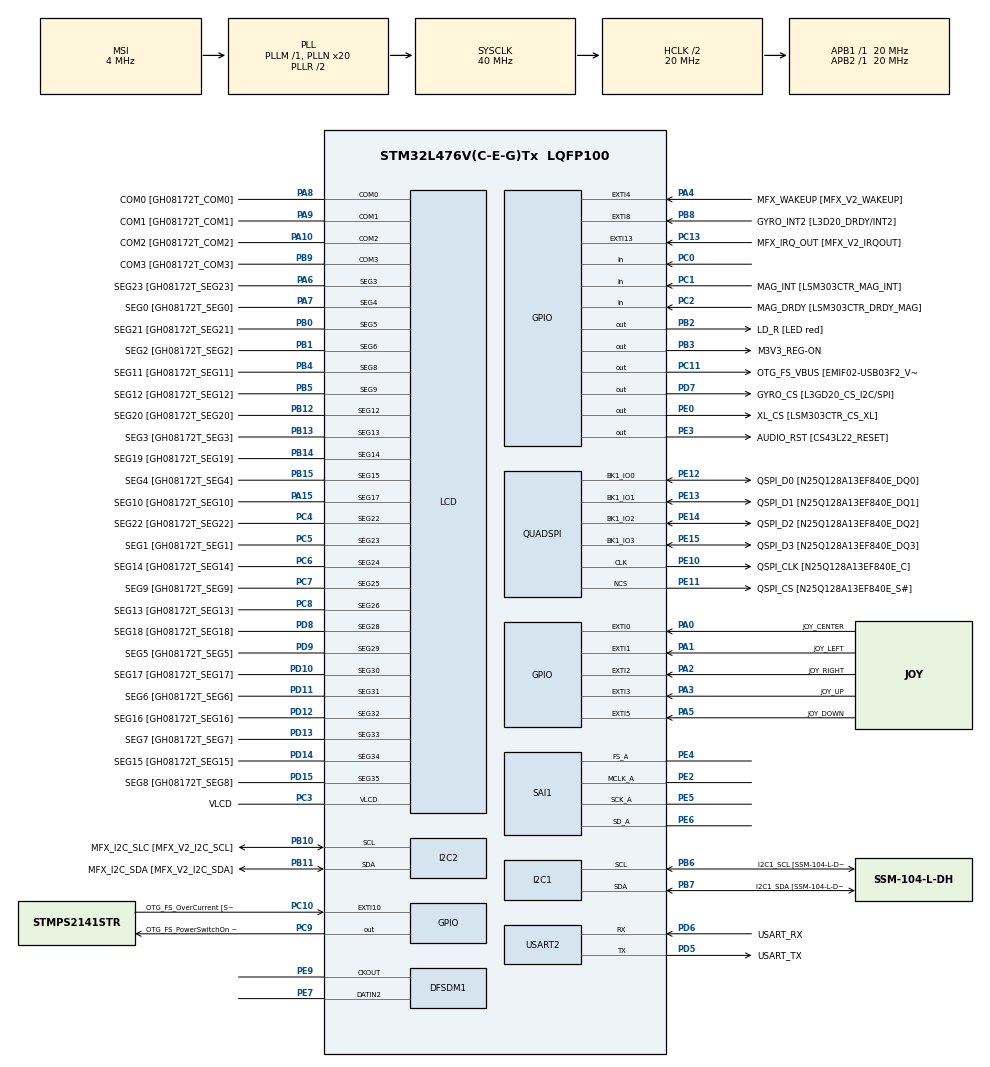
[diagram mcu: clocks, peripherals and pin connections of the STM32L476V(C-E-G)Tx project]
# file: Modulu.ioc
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DFSDM1.Divider=4
DFSDM1.DmaMode_reg_FIL0=ENABLE
DFSDM1.FastMode_reg_FIL0=ENABLE
DFSDM1.Filter_injChannel2_FIL0=DFSDM_CHANNEL_2
DFSDM1.Filter_regChannel_FIL0=DFSDM_CHANNEL_2
DFSDM1.Fosr_FIL0=64
DFSDM1.Oversampling_CH2=10
DFSDM1.RightBitShift_CH2=2
DFSDM1.ScanMode_inj_FIL0=ENABLE
DFSDM1.Selection=DFSDM_CHANNEL_OUTPUT_CLOCK_AUDIO
DFSDM1.SincOrder_FIL0=DFSDM_FILTER_SINC3_ORDER
Dma.DFSDM1_FLT0.1.Direction=DMA_PERIPH_TO_MEMORY
Dma.DFSDM1_FLT0.1.Instance=DMA1_Channel4
Dma.DFSDM1_FLT0.1.MemDataAlignment=DMA_MDATAALIGN_WORD
Dma.DFSDM1_FLT0.1.MemInc=DMA_MINC_ENABLE
Dma.DFSDM1_FLT0.1.Mode=DMA_CIRCULAR
Dma.DFSDM1_FLT0.1.PeriphDataAlignment=DMA_PDATAALIGN_WORD
Dma.DFSDM1_FLT0.1.PeriphInc=DMA_PINC_DISABLE
Dma.DFSDM1_FLT0.1.Priority=DMA_PRIORITY_VERY_HIGH
Dma.Request0=SAI1_A
Dma.Request1=DFSDM1_FLT0
Dma.SAI1_A.0.Direction=DMA_MEMORY_TO_PERIPH
Dma.SAI1_A.0.Instance=DMA2_Channel1
Dma.SAI1_A.0.MemDataAlignment=DMA_MDATAALIGN_HALFWORD
Dma.SAI1_A.0.MemInc=DMA_MINC_ENABLE
Dma.SAI1_A.0.Mode=DMA_CIRCULAR
Dma.SAI1_A.0.PeriphDataAlignment=DMA_PDATAALIGN_HALFWORD
Dma.SAI1_A.0.PeriphInc=DMA_PINC_DISABLE
Dma.SAI1_A.0.Priority=DMA_PRIORITY_HIGH
I2C1.Timing=0x00404C74
I2C2.Timing=0x00404C74
Mcu.Family=STM32L4
Mcu.Name=STM32L476V(C-E-G)Tx
Mcu.Package=LQFP100
NVIC.DFSDM1_FLT0_IRQn=true\:0\:0\:false\:false\:true\:true\:true\:true
NVIC.DMA1_Channel4_IRQn=true\:0\:0\:false\:false\:true\:false\:true\:true
NVIC.DMA2_Channel1_IRQn=true\:0\:0\:false\:false\:true\:false\:true\:true
NVIC.EXTI0_IRQn=true\:0\:0\:false\:false\:true\:true\:true\:true
NVIC.EXTI1_IRQn=true\:0\:0\:false\:false\:true\:true\:true\:true
NVIC.EXTI2_IRQn=true\:0\:0\:false\:false\:true\:true\:true\:true
NVIC.EXTI3_IRQn=true\:0\:0\:false\:false\:true\:true\:true\:true
NVIC.EXTI9_5_IRQn=true\:0\:0\:false\:false\:true\:true\:true\:true
NVIC.PVD_PVM_IRQn=true\:0\:0\:false\:false\:true\:true\:true\:true
NVIC.PriorityGroup=NVIC_PRIORITYGROUP_4
NVIC.SAI1_IRQn=true\:0\:0\:false\:false\:true\:true\:true\:true
NVIC.TIM6_DAC_IRQn=true\:0\:0\:false\:false\:true\:true\:true\:true
NVIC.TIM7_IRQn=true\:0\:0\:false\:false\:true\:true\:true\:true
PA0.GPIO_Label=JOY_CENTER
PA0.GPIO_ModeDefaultEXTI=GPIO_MODE_IT_RISING
PA0.Signal=GPXTI0
PA1.GPIO_Label=JOY_LEFT
PA1.GPIO_PuPd=GPIO_PULLDOWN
PA1.Signal=GPXTI1
PA10.GPIO_Label=COM2 [GH08172T_COM2]
PA10.GPIO_Mode=GPIO_MODE_AF_PP
PA10.GPIO_PuPd=GPIO_NOPULL
PA10.GPIO_Speed=GPIO_SPEED_FREQ_LOW
PA10.Mode=1/4 Duty Cycle
PA10.Signal=LCD_COM2
PA11.GPIO_Label=OTG_FS_DM [EMIF02-USB03F2_D-out]
PA11.GPIO_Mode=GPIO_MODE_AF_PP
PA11.GPIO_PuPd=GPIO_NOPULL
PA11.GPIO_Speed=GPIO_SPEED_FREQ_VERY_HIGH
PA11.Signal=USB_OTG_FS_DM
PA12.GPIO_Label=OTG_FS_DP [EMIF02-USB03F2_D+out]
PA12.GPIO_Mode=GPIO_MODE_AF_PP
PA12.GPIO_PuPd=GPIO_NOPULL
PA12.GPIO_Speed=GPIO_SPEED_FREQ_VERY_HIGH
PA12.Signal=USB_OTG_FS_DP
PA13\ (JTMS-SWDIO).GPIO_Label=SWDIO
PA13\ (JTMS-SWDIO).Mode=Serial_Wire
PA13\ (JTMS-SWDIO).Signal=SYS_JTMS-SWDIO
PA14\ (JTCK-SWCLK).GPIO_Label=SWCLK
PA14\ (JTCK-SWCLK).Mode=Serial_Wire
PA14\ (JTCK-SWCLK).Signal=SYS_JTCK-SWCLK
PA15\ (JTDI).GPIO_Label=SEG10 [GH08172T_SEG10]
PA15\ (JTDI).GPIO_Mode=GPIO_MODE_AF_PP
PA15\ (JTDI).GPIO_PuPd=GPIO_NOPULL
PA15\ (JTDI).GPIO_Speed=GPIO_SPEED_FREQ_LOW
PA15\ (JTDI).Mode=SEG17
PA15\ (JTDI).Signal=LCD_SEG17
PA2.GPIO_Label=JOY_RIGHT
PA2.GPIO_PuPd=GPIO_PULLDOWN
PA2.Signal=GPXTI2
PA3.GPIO_Label=JOY_UP
PA3.GPIO_PuPd=GPIO_PULLDOWN
PA3.Signal=GPXTI3
PA4.GPIO_Label=MFX_WAKEUP [MFX_V2_WAKEUP]
PA4.GPIO_ModeDefaultEXTI=GPIO_MODE_EVT_RISING
PA4.GPIO_PuPd=GPIO_NOPULL
PA4.Signal=GPXTI4
PA5.GPIO_Label=JOY_DOWN
PA5.GPIO_PuPd=GPIO_PULLDOWN
PA5.Signal=GPXTI5
PA6.GPIO_Label=SEG23 [GH08172T_SEG23]
PA6.GPIO_Mode=GPIO_MODE_AF_PP
PA6.GPIO_PuPd=GPIO_NOPULL
PA6.GPIO_Speed=GPIO_SPEED_FREQ_LOW
PA6.Mode=SEG3
PA6.Signal=LCD_SEG3
PA7.GPIO_Label=SEG0 [GH08172T_SEG0]
PA7.GPIO_Mode=GPIO_MODE_AF_PP
PA7.GPIO_PuPd=GPIO_NOPULL
PA7.GPIO_Speed=GPIO_SPEED_FREQ_LOW
PA7.Mode=SEG4
PA7.Signal=LCD_SEG4
PA8.GPIO_Label=COM0 [GH08172T_COM0]
PA8.GPIO_Mode=GPIO_MODE_AF_PP
PA8.GPIO_PuPd=GPIO_NOPULL
PA8.GPIO_Speed=GPIO_SPEED_FREQ_LOW
PA8.Mode=1/4 Duty Cycle
PA8.Signal=LCD_COM0
PA9.GPIO_Label=COM1 [GH08172T_COM1]
PA9.GPIO_Mode=GPIO_MODE_AF_PP
PA9.GPIO_PuPd=GPIO_NOPULL
PA9.GPIO_Speed=GPIO_SPEED_FREQ_LOW
PA9.Mode=1/4 Duty Cycle
PA9.Signal=LCD_COM1
PB0.GPIO_Label=SEG21 [GH08172T_SEG21]
PB0.GPIO_Mode=GPIO_MODE_AF_PP
PB0.GPIO_PuPd=GPIO_NOPULL
PB0.GPIO_Speed=GPIO_SPEED_FREQ_LOW
PB0.Mode=SEG5
PB0.Signal=LCD_SEG5
PB1.GPIO_Label=SEG2 [GH08172T_SEG2]
PB1.GPIO_Mode=GPIO_MODE_AF_PP
PB1.GPIO_PuPd=GPIO_NOPULL
PB1.GPIO_Speed=GPIO_SPEED_FREQ_LOW
PB1.Mode=SEG6
PB1.Signal=LCD_SEG6
PB10.GPIO_Label=MFX_I2C_SLC [MFX_V2_I2C_SCL]
PB10.GPIO_Mode=GPIO_MODE_AF_OD
PB10.GPIO_Pu=GPIO_PULLUP
PB10.GPIO_Speed=GPIO_SPEED_FREQ_VERY_HIGH
PB10.Mode=I2C
PB10.Signal=I2C2_SCL
PB11.GPIO_Label=MFX_I2C_SDA [MFX_V2_I2C_SDA]
PB11.GPIO_Mode=GPIO_MODE_AF_OD
PB11.GPIO_Pu=GPIO_PULLUP
PB11.GPIO_Speed=GPIO_SPEED_FREQ_VERY_HIGH
PB11.Mode=I2C
PB11.Signal=I2C2_SDA
PB12.GPIO_Label=SEG20 [GH08172T_SEG20]
PB12.GPIO_Mode=GPIO_MODE_AF_PP
PB12.GPIO_PuPd=GPIO_NOPULL
PB12.GPIO_Speed=GPIO_SPEED_FREQ_LOW
PB12.Mode=SEG12
PB12.Signal=LCD_SEG12
PB13.GPIO_Label=SEG3 [GH08172T_SEG3]
PB13.GPIO_Mode=GPIO_MODE_AF_PP
PB13.GPIO_PuPd=GPIO_NOPULL
PB13.GPIO_Speed=GPIO_SPEED_FREQ_LOW
PB13.Mode=SEG13
PB13.Signal=LCD_SEG13
PB14.GPIO_Label=SEG19 [GH08172T_SEG19]
PB14.GPIO_Mode=GPIO_MODE_AF_PP
PB14.GPIO_PuPd=GPIO_NOPULL
PB14.GPIO_Speed=GPIO_SPEED_FREQ_LOW
PB14.Mode=SEG14
PB14.Signal=LCD_SEG14
PB15.GPIO_Label=SEG4 [GH08172T_SEG4]
PB15.GPIO_Mode=GPIO_MODE_AF_PP
PB15.GPIO_PuPd=GPIO_NOPULL
PB15.GPIO_Speed=GPIO_SPEED_FREQ_LOW
PB15.Mode=SEG15
PB15.Signal=LCD_SEG15
PB2.GPIO_Label=LD_R [LED red]
PB2.GPIO_ModeDefaultOutputPP=GPIO_MODE_OUTPUT_PP
PB2.GPIO_PuPd=GPIO_PULLUP
PB2.GPIO_Speed=GPIO_SPEED_FREQ_VERY_HIGH
PB2.Signal=GPIO_Output
PB3\ (JTDO-TRACESWO).GPIO_Label=M3V3_REG-ON
PB3\ (JTDO-TRACESWO).GPIO_ModeDefaultOutputPP=GPIO_MODE_OUTPUT_PP
PB3\ (JTDO-TRACESWO).GPIO_PuPd=GPIO_NOPULL
PB3\ (JTDO-TRACESWO).GPIO_Speed=GPIO_SPEED_FREQ_LOW
PB3\ (JTDO-TRACESWO).Signal=GPIO_Output
PB4\ (NJTRST).GPIO_Label=SEG11 [GH08172T_SEG11]
PB4\ (NJTRST).GPIO_Mode=GPIO_MODE_AF_PP
PB4\ (NJTRST).GPIO_PuPd=GPIO_NOPULL
PB4\ (NJTRST).GPIO_Speed=GPIO_SPEED_FREQ_LOW
PB4\ (NJTRST).Mode=SEG8
PB4\ (NJTRST).Signal=LCD_SEG8
PB5.GPIO_Label=SEG12 [GH08172T_SEG12]
PB5.GPIO_Mode=GPIO_MODE_AF_PP
PB5.GPIO_PuPd=GPIO_NOPULL
PB5.GPIO_Speed=GPIO_SPEED_FREQ_LOW
PB5.Mode=SEG9
PB5.Signal=LCD_SEG9
PB6.GPIO_FM6=__NULL
PB6.GPIO_Label=I2C1_SCL [SSM-104-L-DH_SCL]
PB6.GPIO_Mode=GPIO_MODE_AF_OD
PB6.GPIO_Pu=GPIO_PULLUP
PB6.GPIO_Speed=GPIO_SPEED_FREQ_VERY_HIGH
PB6.Mode=I2C
PB6.Signal=I2C1_SCL
PB7.GPIO_FM7=__NULL
PB7.GPIO_Label=I2C1_SDA [SSM-104-L-DH_SDA]
PB7.GPIO_Mode=GPIO_MODE_AF_OD
PB7.GPIO_Pu=GPIO_PULLUP
PB7.GPIO_Speed=GPIO_SPEED_FREQ_VERY_HIGH
PB7.Mode=I2C
PB7.Signal=I2C1_SDA
PB8.GPIO_Label=GYRO_INT2 [L3D20_DRDY/INT2]
PB8.GPIO_ModeDefaultEXTI=GPIO_MODE_EVT_RISING
PB8.GPIO_PuPd=GPIO_NOPULL
PB8.Signal=GPXTI8
PB9.GPIO_FM9=__NULL
PB9.GPIO_Label=COM3 [GH08172T_COM3]
PB9.GPIO_Mode=GPIO_MODE_AF_PP
PB9.GPIO_PuPd=GPIO_NOPULL
PB9.GPIO_Speed=GPIO_SPEED_FREQ_LOW
PB9.Mode=1/4 Duty Cycle
PB9.Signal=LCD_COM3
PC0.Signal=GPIO_Input
PC1.GPIO_Label=MAG_INT [LSM303CTR_MAG_INT]
PC1.GPIO_Mode=GPIO_MODE_INPUT
PC1.GPIO_PuPd=GPIO_NOPULL
PC1.Signal=GPIO_Input
PC10.GPIO_Label=OTG_FS_OverCurrent [STMPS2141STR_FAULT]
PC10.GPIO_ModeDefaultEXTI=GPIO_MODE_EVT_RISING
PC10.GPIO_PuPd=GPIO_NOPULL
PC10.Signal=GPXTI10
PC11.GPIO_Label=OTG_FS_VBUS [EMIF02-USB03F2_Vbus]
PC11.GPIO_ModeDefaultOutputPP=GPIO_MODE_OUTPUT_PP
PC11.GPIO_PuPd=GPIO_NOPULL
PC11.GPIO_Speed=GPIO_SPEED_FREQ_LOW
PC11.Signal=GPIO_Output
PC13.GPIO_Label=MFX_IRQ_OUT [MFX_V2_IRQOUT]
PC13.GPIO_ModeDefaultEXTI=GPIO_MODE_EVT_RISING
PC13.GPIO_PuPd=GPIO_NOPULL
PC13.Signal=GPXTI13
PC14-OSC32_IN\ (PC14).Mode=LSE-External-Oscillator
PC14-OSC32_IN\ (PC14).Signal=RCC_OSC32_IN
PC15-OSC32_OUT\ (PC15).Mode=LSE-External-Oscillator
PC15-OSC32_OUT\ (PC15).Signal=RCC_OSC32_OUT
PC2.GPIO_Label=MAG_DRDY [LSM303CTR_DRDY_MAG]
PC2.GPIO_Mode=GPIO_MODE_INPUT
PC2.GPIO_PuPd=GPIO_NOPULL
PC2.Signal=GPIO_Input
PC3.GPIO_Label=VLCD
PC3.GPIO_Mode=GPIO_MODE_AF_PP
PC3.GPIO_PuPd=GPIO_NOPULL
PC3.GPIO_Speed=GPIO_SPEED_FREQ_LOW
PC3.Mode=1/4 Duty Cycle
PC3.Signal=LCD_VLCD
PC4.GPIO_Label=SEG22 [GH08172T_SEG22]
PC4.GPIO_Mode=GPIO_MODE_AF_PP
PC4.GPIO_PuPd=GPIO_NOPULL
PC4.GPIO_Speed=GPIO_SPEED_FREQ_LOW
PC4.Mode=SEG22
PC4.Signal=LCD_SEG22
PC5.GPIO_Label=SEG1 [GH08172T_SEG1]
PC5.GPIO_Mode=GPIO_MODE_AF_PP
PC5.GPIO_PuPd=GPIO_NOPULL
PC5.GPIO_Speed=GPIO_SPEED_FREQ_LOW
PC5.Mode=SEG23
PC5.Signal=LCD_SEG23
PC6.GPIO_Label=SEG14 [GH08172T_SEG14]
PC6.GPIO_Mode=GPIO_MODE_AF_PP
PC6.GPIO_PuPd=GPIO_NOPULL
PC6.GPIO_Speed=GPIO_SPEED_FREQ_LOW
PC6.Mode=SEG24
PC6.Signal=LCD_SEG24
PC7.GPIO_Label=SEG9 [GH08172T_SEG9]
PC7.GPIO_Mode=GPIO_MODE_AF_PP
PC7.GPIO_PuPd=GPIO_NOPULL
PC7.GPIO_Speed=GPIO_SPEED_FREQ_LOW
PC7.Mode=SEG25
PC7.Signal=LCD_SEG25
PC8.GPIO_Label=SEG13 [GH08172T_SEG13]
PC8.GPIO_Mode=GPIO_MODE_AF_PP
PC8.GPIO_PuPd=GPIO_NOPULL
PC8.GPIO_Speed=GPIO_SPEED_FREQ_LOW
PC8.Mode=SEG26
PC8.Signal=LCD_SEG26
PC9.GPIO_Label=OTG_FS_PowerSwitchOn [STMPS2141STR_EN]
PC9.GPIO_ModeDefaultOutputPP=GPIO_MODE_OUTPUT_PP
PC9.GPIO_PuPd=GPIO_NOPULL
PC9.GPIO_Speed=GPIO_SPEED_FREQ_LOW
PC9.PinState=GPIO_PIN_SET
PC9.Signal=GPIO_Output
PD1.GPIO_Label=MEMS_SCK [L3GD20_SCL/SPC]
PD1.GPIO_Mode=GPIO_MODE_AF_PP
PD1.GPIO_PuPd=GPIO_NOPULL
PD1.GPIO_Speed=GPIO_SPEED_FREQ_VERY_HIGH
PD1.Signal=SPI2_SCK
PD10.GPIO_Label=SEG17 [GH08172T_SEG17]
PD10.GPIO_Mode=GPIO_MODE_AF_PP
PD10.GPIO_PuPd=GPIO_NOPULL
PD10.GPIO_Speed=GPIO_SPEED_FREQ_LOW
PD10.Mode=SEG30
PD10.Signal=LCD_SEG30
PD11.GPIO_Label=SEG6 [GH08172T_SEG6]
PD11.GPIO_Mode=GPIO_MODE_AF_PP
PD11.GPIO_PuPd=GPIO_NOPULL
PD11.GPIO_Speed=GPIO_SPEED_FREQ_LOW
PD11.Mode=SEG31
PD11.Signal=LCD_SEG31
PD12.GPIO_Label=SEG16 [GH08172T_SEG16]
PD12.GPIO_Mode=GPIO_MODE_AF_PP
PD12.GPIO_PuPd=GPIO_NOPULL
PD12.GPIO_Speed=GPIO_SPEED_FREQ_LOW
PD12.Mode=SEG32
PD12.Signal=LCD_SEG32
PD13.GPIO_Label=SEG7 [GH08172T_SEG7]
PD13.GPIO_Mode=GPIO_MODE_AF_PP
PD13.GPIO_PuPd=GPIO_NOPULL
PD13.GPIO_Speed=GPIO_SPEED_FREQ_LOW
PD13.Mode=SEG33
PD13.Signal=LCD_SEG33
PD14.GPIO_Label=SEG15 [GH08172T_SEG15]
PD14.GPIO_Mode=GPIO_MODE_AF_PP
PD14.GPIO_PuPd=GPIO_NOPULL
PD14.GPIO_Speed=GPIO_SPEED_FREQ_LOW
PD14.Mode=SEG34
PD14.Signal=LCD_SEG34
PD15.GPIO_Label=SEG8 [GH08172T_SEG8]
PD15.GPIO_Mode=GPIO_MODE_AF_PP
PD15.GPIO_PuPd=GPIO_NOPULL
PD15.GPIO_Speed=GPIO_SPEED_FREQ_LOW
PD15.Mode=SEG35
PD15.Signal=LCD_SEG35
PD3.GPIO_Label=MEMS_MISO [L3GD20_SA0/SDO]
PD3.GPIO_Mode=GPIO_MODE_AF_PP
PD3.GPIO_PuPd=GPIO_NOPULL
PD3.GPIO_Speed=GPIO_SPEED_FREQ_VERY_HIGH
PD3.Signal=SPI2_MISO
PD4.GPIO_Label=MEMS_MOSI [L3GD20_SDA/SDI/SDO]
PD4.GPIO_Mode=GPIO_MODE_AF_PP
PD4.GPIO_PuPd=GPIO_NOPULL
PD4.GPIO_Speed=GPIO_SPEED_FREQ_VERY_HIGH
PD4.Signal=SPI2_MOSI
PD5.GPIO_Label=USART_TX
PD5.GPIO_Mode=GPIO_MODE_AF_PP
PD5.GPIO_PuPd=GPIO_PULLUP
PD5.GPIO_Speed=GPIO_SPEED_FREQ_VERY_HIGH
PD5.Mode=Asynchronous
PD5.Signal=USART2_TX
PD6.GPIO_Label=USART_RX
PD6.GPIO_Mode=GPIO_MODE_AF_PP
PD6.GPIO_PuPd=GPIO_PULLUP
PD6.GPIO_Speed=GPIO_SPEED_FREQ_VERY_HIGH
PD6.Mode=Asynchronous
PD6.Signal=USART2_RX
PD7.GPIO_Label=GYRO_CS [L3GD20_CS_I2C/SPI]
PD7.GPIO_ModeDefaultOutputPP=GPIO_MODE_OUTPUT_PP
PD7.GPIO_PuPd=GPIO_NOPULL
PD7.GPIO_Speed=GPIO_SPEED_FREQ_VERY_HIGH
PD7.Signal=GPIO_Output
PD8.GPIO_Label=SEG18 [GH08172T_SEG18]
PD8.GPIO_Mode=GPIO_MODE_AF_PP
PD8.GPIO_PuPd=GPIO_NOPULL
PD8.GPIO_Speed=GPIO_SPEED_FREQ_LOW
PD8.Mode=SEG28
PD8.Signal=LCD_SEG28
PD9.GPIO_Label=SEG5 [GH08172T_SEG5]
PD9.GPIO_Mode=GPIO_MODE_AF_PP
PD9.GPIO_PuPd=GPIO_NOPULL
PD9.GPIO_Speed=GPIO_SPEED_FREQ_LOW
PD9.Mode=SEG29
PD9.Signal=LCD_SEG29
PE0.GPIO_Label=XL_CS [LSM303CTR_CS_XL]
PE0.GPIO_ModeDefaultOutputPP=GPIO_MODE_OUTPUT_PP
PE0.GPIO_PuPd=GPIO_NOPULL
PE0.GPIO_Speed=GPIO_SPEED_FREQ_LOW
PE0.Signal=GPIO_Output
PE10.GPIO_Label=QSPI_CLK [N25Q128A13EF840E_C]
PE10.GPIO_Mode=GPIO_MODE_AF_PP
PE10.GPIO_PuPd=GPIO_NOPULL
PE10.GPIO_Speed=GPIO_SPEED_FREQ_VERY_HIGH
PE10.Mode=Single Bank
PE10.Signal=QUADSPI_CLK
PE11.GPIO_Label=QSPI_CS [N25Q128A13EF840E_S\#]
PE11.GPIO_Mode=GPIO_MODE_AF_PP
PE11.GPIO_PuPd=GPIO_NOPULL
PE11.GPIO_Speed=GPIO_SPEED_FREQ_VERY_HIGH
PE11.Mode=Single Bank
PE11.Signal=QUADSPI_NCS
PE12.GPIO_Label=QSPI_D0 [N25Q128A13EF840E_DQ0]
PE12.GPIO_Mode=GPIO_MODE_AF_PP
PE12.GPIO_PuPd=GPIO_NOPULL
PE12.GPIO_Speed=GPIO_SPEED_FREQ_VERY_HIGH
PE12.Mode=Single Bank
PE12.Signal=QUADSPI_BK1_IO0
PE13.GPIO_Label=QSPI_D1 [N25Q128A13EF840E_DQ1]
PE13.GPIO_Mode=GPIO_MODE_AF_PP
PE13.GPIO_PuPd=GPIO_NOPULL
PE13.GPIO_Speed=GPIO_SPEED_FREQ_VERY_HIGH
PE13.Mode=Single Bank
PE13.Signal=QUADSPI_BK1_IO1
PE14.GPIO_Label=QSPI_D2 [N25Q128A13EF840E_DQ2]
PE14.GPIO_Mode=GPIO_MODE_AF_PP
PE14.GPIO_PuPd=GPIO_NOPULL
PE14.GPIO_Speed=GPIO_SPEED_FREQ_VERY_HIGH
PE14.Mode=Single Bank
PE14.Signal=QUADSPI_BK1_IO2
PE15.GPIO_Label=QSPI_D3 [N25Q128A13EF840E_DQ3]
PE15.GPIO_Mode=GPIO_MODE_AF_PP
PE15.GPIO_PuPd=GPIO_NOPULL
PE15.GPIO_Speed=GPIO_SPEED_FREQ_VERY_HIGH
PE15.Mode=Single Bank
PE15.Signal=QUADSPI_BK1_IO3
PE2.Mode=SAI_A_MasterWithClock
PE2.Signal=SAI1_MCLK_A
PE3.GPIO_Label=AUDIO_RST [CS43L22_RESET]
PE3.GPIO_ModeDefaultOutputPP=GPIO_MODE_OUTPUT_PP
PE3.GPIO_PuPd=GPIO_NOPULL
PE3.GPIO_Speed=GPIO_SPEED_FREQ_HIGH
PE3.Signal=GPIO_Output
PE4.Mode=SAI_A_MasterWithClock
PE4.Signal=SAI1_FS_A
PE5.Mode=SAI_A_MasterWithClock
PE5.Signal=SAI1_SCK_A
PE6.Mode=SAI_A_MasterWithClock
PE6.Signal=SAI1_SD_A
PE7.Signal=S_DATAIN2DFSDM1
PE9.Signal=S_CKOUTDFSDM1
PH0-OSC_IN\ (PH0).Mode=HSE-External-Oscillator
PH0-OSC_IN\ (PH0).Signal=RCC_OSC_IN
PH1-OSC_OUT\ (PH1).Mode=HSE-External-Oscillator
PH1-OSC_OUT\ (PH1).Signal=RCC_OSC_OUT
ProjectManager.HeapSize=0x200
ProjectManager.StackSize=0x400
ProjectManager.TargetToolchain=STM32CubeIDE
QUADSPI.ClockPrescaler=1
QUADSPI.FifoThreshold=4
QUADSPI.FlashSize=24
QUADSPI.SampleShifting=QSPI_SAMPLE_SHIFTING_HALFCYCLE
RCC.ADCFreq_Value=48000000
RCC.AHBCLKDivider=RCC_SYSCLK_DIV2
RCC.AHBFreq_Value=20000000
RCC.APB1Freq_Value=20000000
RCC.APB1TimFreq_Value=20000000
RCC.APB2Freq_Value=20000000
RCC.APB2TimFreq_Value=20000000
RCC.CortexFreq_Value=20000000
RCC.HCLKFreq_Value=20000000
RCC.HSE_VALUE=8000000
RCC.HSI_VALUE=16000000
RCC.MSI_VALUE=4000000
RCC.PLLN=20
RCC.PLLSAI1N=24
RCC.PREFETCH_ENABLE=1
RCC.SYSCLKFreq_VALUE=40000000
RCC.SYSCLKSource=RCC_SYSCLKSOURCE_PLLCLK
RCC.USBFreq_Value=48000000
RCC.VCOOutputFreq_Value=80000000
SAI1.ActiveFrameLength-SAI_A_MasterWithClock=16
SAI1.AudioFrequency-SAI_A_MasterWithClock=SAI_AUDIO_FREQUENCY_44K
SAI1.DataSize-SAI_A_MasterWithClock=SAI_DATASIZE_16
SAI1.ErrorAudioFreq-SAI_A_MasterWithClock=21.47 %
SAI1.FIFOThreshold-SAI_A_MasterWithClock=SAI_FIFOTHRESHOLD_1QF
SAI1.FSDefinition-SAI_A_MasterWithClock=SAI_FS_CHANNEL_IDENTIFICATION
SAI1.FSOffset-SAI_A_MasterWithClock=SAI_FS_BEFOREFIRSTBIT
SAI1.FrameLength-SAI_A_MasterWithClock=32
SAI1.Instance-SAI_A_MasterWithClock=SAI$Index_Block_A
SAI1.MClockEnable-SAI_A_MasterWithClock=SAI_MASTERCLOCK_ENABLE
SAI1.NoDivider-SAI_A_MasterWithClock=SAI_MASTERDIVIDER_ENABLE
SAI1.OutputDrive-SAI_A_MasterWithClock=SAI_OUTPUTDRIVE_ENABLE
SAI1.RealAudioFreq-SAI_A_MasterWithClock=53.571 KHz
SAI1.SlotActive-SAI_A_MasterWithClock=0x00000003
SAI1.SlotNumber-SAI_A_MasterWithClock=2
SAI1.VirtualMode-SAI_A_MasterWithClock=VM_MASTER
SAI1.VirtualSlotActive-SAI_A_MasterWithClock=SAI_SLOT_USERSETTING
SAI1.VirtualSlotActive0-SAI_A_MasterWithClock=true
SAI1.VirtualSlotActive1-SAI_A_MasterWithClock=true
SH.S_CKOUTDFSDM1.0=DFSDM1_CKOUT,PDM_SPI_input_from_ch2_and_internal_clock
SH.S_DATAIN2DFSDM1.0=DFSDM1_DATIN2,PDM_SPI_input_from_ch2_and_internal_clock
STMicroelectronics.X-CUBE-ALGOBUILD.1.3.0.LibraryCcDSPOoLibraryJjDSPOoLibrary=true
STMicroelectronics.X-CUBE-AZRTOS-L4.2.0.0.STM32CubeIiBSPIiComponentsCcBoardOoPartJjQuadSPIJjN25Q128A=true
STMicroelectronics.X-CUBE-AZRTOS-L4.2.0.0_IsAnAzureRtosMw=true
TIM6.Prescaler=1000
TIM6.TIM_MasterOutputTrigger=TIM_TRGO_RESET
TIM7.Prescaler=250
USART2.VirtualMode-Asynchronous=VM_ASYNC
VP_STMicroelectronics.X-CUBE-ALGOBUILD_VS_DSPOoLibraryJjLibrary_1.3.0_1.3.0.Mode=DSPOoLibraryJjLibrary
VP_STMicroelectronics.X-CUBE-AZRTOS-L4_VS_BoardOoPartJjSTM32CubeIiBSPIiComponents_2.1.0_2.0.0.Mode=BoardOoPartJjSTM32CubeIiBSPIiComponents
VP_TIM6_VS_ClockSourceINT.Mode=Enable_Timer
VP_TIM7_VS_ClockSourceINT.Mode=Enable_Timer
board=STM32L476G-DISCO

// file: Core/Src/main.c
/* USER CODE BEGIN Header */
/**
  ******************************************************************************
  * @file           : main.c
  * @brief          : Main program body
  ******************************************************************************
  * @attention
  *
  * Copyright (c) 2024 STMicroelectronics.
  * All rights reserved.
  *
  * This software is licensed under terms that can be found in the LICENSE file
  * in the root directory of this software component.
  * If no LICENSE file comes with this software, it is provided AS-IS.
  *
  ******************************************************************************
  */
/* USER CODE END Header */
#include "main.h"

/* USER CODE BEGIN Includes */

#include "../../../Drivers/BSP/Components/Common/audio.h"
#include "../../../Drivers/BSP/Components/cs43l22/cs43l22.h"

#include <stdlib.h>
#include <stdio.h>
#include <string.h>
#include <math.h>

#include "modulus_modes.h"

//#include "../Components/Common/audio.h"

/* USER CODE END Includes */

DFSDM_Filter_HandleTypeDef hdfsdm1_filter0;
DFSDM_Channel_HandleTypeDef hdfsdm1_channel2;
DMA_HandleTypeDef hdma_dfsdm1_flt0;

I2C_HandleTypeDef hi2c1;
I2C_HandleTypeDef hi2c2;

LCD_HandleTypeDef hlcd;

QSPI_HandleTypeDef hqspi;

SAI_HandleTypeDef hsai_BlockA1;
DMA_HandleTypeDef hdma_sai1_a;

TIM_HandleTypeDef htim6;
TIM_HandleTypeDef htim7;

UART_HandleTypeDef huart2;

/* USER CODE BEGIN PV */

AUDIO_DrvTypeDef  *audio_drv;

/* USER CODE END PV */

void SystemClock_Config(void);
static void MX_GPIO_Init(void);
static void MX_DMA_Init(void);
static void MX_I2C1_Init(void);
static void MX_I2C2_Init(void);
static void MX_LCD_Init(void);
static void MX_QUADSPI_Init(void);
static void MX_USART2_UART_Init(void);
static void MX_TIM6_Init(void);
static void MX_TIM7_Init(void);
static void MX_DFSDM1_Init(void);
static void MX_SAI1_Init(void);
/* USER CODE BEGIN PFP */

#define SaturaLH(N, L, H) (((N)<(L))?(L):(((N)>(H))?(H):(N)))

/* USER CODE END PFP */

/* USER CODE BEGIN 0 */

static menu_mode_t menu_mode = SELECT_MODULATION;

static volatile bool ModeChanged = false;

// refresh LCD display
static volatile bool LCDRefresh = false;

// apply settings
static volatile bool UpdateSettings = false;

// save settings to flash
static volatile bool SaveSettings = false;

static modulus_config_t config;

int32_t dma_rx_buffer[DMA_RX_BUFFER_SIZE*2]={0};

int16_t dma_tx_buffer[DMA_TX_BUFFER_SIZE*2]={0};

float audio_input_buffer[DMA_RX_BUFFER_SIZE]={0.0};

float audio_output_buffer[DMA_TX_BUFFER_SIZE]={0.0};

volatile size_t dma_buffer_offset=0;

volatile bool ProcessAudio=false;

int32_t* getBuffer()
{
	return dma_rx_buffer+dma_buffer_offset;
}

void HAL_DFSDM_FilterRegConvCpltCallback(DFSDM_Filter_HandleTypeDef *hdfsdm_filter)
{
	ProcessAudio=true;
	dma_buffer_offset=DMA_RX_BUFFER_SIZE;
	//HAL_DFSDM_FilterRegularStart_DMA(&hdfsdm1_filter0, dma_rx_buffer, DMA_RX_BUFFER_SIZE*2);
}

void HAL_DFSDM_FilterRegConvHalfCpltCallback(DFSDM_Filter_HandleTypeDef *hdfsdm_filter)
{
	ProcessAudio=true;
	dma_buffer_offset=0;
}

void from_uint8_to_floats(int32_t* input,float* output)
{

	for(size_t i=0;i<(DMA_RX_BUFFER_SIZE);++i)
	{
		output[i] = SaturaLH((input[i] >> 8), -32768, 32767)/32767.f;
	}

}

void from_float_to_uint8(float* input,int16_t* output,size_t input_size)
{
	for(size_t i=0;i<input_size;++i)
	{
		output[i*2]=(int16_t)(input[i]*32768.f);
		output[i*2 +1]=output[i*2];
	}
}

void switchScreen()
{
	HAL_TIM_Base_Stop_IT(&htim7);
	LCDRefresh = false;

	switch(menu_mode)
	{
		case SELECT_MODULATION:
			LCD_Clear(&hlcd);
			LCD_DisplayStr(&hlcd,"MOD");
		break;
		case CHANGE_CONTRAST:
			LCD_Clear(&hlcd);
			LCD_DisplayStr(&hlcd,"CONT");
		break;
		case CHANGE_VOLUME:
			LCD_Clear(&hlcd);
			LCD_DisplayStr(&hlcd,"VOL");
		break;
		case ACCEPT_CHANGES:
			LCD_Clear(&hlcd);
			LCD_DisplayStr(&hlcd,"SAVE?");
		break;
	}

	HAL_TIM_Base_Start_IT(&htim6);

}

// menu timer interrupt, used to switch between show menu option and show value
void HAL_TIM_PeriodElapsedCallback(TIM_HandleTypeDef* htim)
{
	if(htim == &htim6)
	{
		// it will run only once
		HAL_TIM_Base_Stop_IT(&htim6);
		HAL_TIM_Base_Start_IT(&htim7);
	}
	else if(htim == &htim7)
	{
		// commence screen update
		LCDRefresh = true;
	}
}

// button interrupt
void HAL_GPIO_EXTI_Callback(uint16_t GPIO_Pin)
{
	switch(GPIO_Pin)
	{
		// left, select modes upward
		case JOY_LEFT_Pin:

			switch(menu_mode)
			{
				case SELECT_MODULATION:
					if( config.mode < MODES_COUNT-1 )
					{
						config.mode++;
					}
				break;
				case CHANGE_CONTRAST:
					if( config.contrast < 255 )
					{
						config.contrast++;
						UpdateSettings=true;
					}
				break;
				case CHANGE_VOLUME:
					if( config.volume < 255 )
					{
						config.volume++;
						UpdateSettings=true;
					}
				break;
				case ACCEPT_CHANGES:

				break;

			}

		break;
			// right, selecr modes backward
		case JOY_RIGHT_Pin:

			switch(menu_mode)
						{
							case SELECT_MODULATION:
								if( config.mode > 0 )
								{
									config.mode--;
								}
							break;
							case CHANGE_CONTRAST:
								if( config.contrast > 0 )
								{
									config.contrast--;
									UpdateSettings=true;
								}
							break;
							case CHANGE_VOLUME:
								if( config.volume > 0 )
								{
									config.volume--;
									UpdateSettings=true;
								}
							break;
							case ACCEPT_CHANGES:

							break;

						}

		break;
			// up
		case JOY_UP_Pin:

			if( menu_mode < ACCEPT_CHANGES)
			{
				menu_mode++;
				ModeChanged=true;
			}

		break;
			// bottom
		case JOY_DOWN_Pin:

			if( menu_mode > SELECT_MODULATION)
			{
				menu_mode--;
				ModeChanged=true;
			}

		break;
			// center
		case JOY_CENTER_Pin:

			if( menu_mode == ACCEPT_CHANGES)
			{
				SaveSettings=true;

			}

		break;
	}
}

// a function to control screen in current mode
void displayScreen()
{
	char msg[6]={0};

	switch(menu_mode)
		{
			case SELECT_MODULATION:
				sprintf(msg,"%u",config.mode);
				LCD_Clear(&hlcd);
				LCD_DisplayStr(&hlcd,msg);
			break;
			case CHANGE_CONTRAST:
				sprintf(msg,"%u",config.contrast);
				LCD_Clear(&hlcd);
				LCD_DisplayStr(&hlcd,msg);
			break;
			case CHANGE_VOLUME:
				sprintf(msg,"%u",config.volume);
				LCD_Clear(&hlcd);
				LCD_DisplayStr(&hlcd,msg);
			break;
			case ACCEPT_CHANGES:
				return;
			break;
		}
}

void audio_init()
{
	if(CS43L22_ID != cs43l22_drv.ReadID(AUDIO_I2C_ADDR))
	  {
	    Error_Handler();
	  }
	  audio_drv = &cs43l22_drv;
	  audio_drv->Reset(AUDIO_I2C_ADDR);
	  if(0 != audio_drv->Init(AUDIO_I2C_ADDR, OUTPUT_DEVICE_HEADPHONE, 90, AUDIO_FREQUENCY_44K))
	  {
	    Error_Handler();
	  }
}

void AUDIO_IO_Init(void)
{
  GPIO_InitTypeDef  GPIO_InitStruct;

  /* Enable Reset GPIO Clock */
  AUDIO_RESET_GPIO_CLK_ENABLE();

  /* Audio reset pin configuration */
  GPIO_InitStruct.Pin = AUDIO_RESET_PIN;
  GPIO_InitStruct.Mode = GPIO_MODE_OUTPUT_PP;
  GPIO_InitStruct.Speed = GPIO_SPEED_FREQ_HIGH;
  GPIO_InitStruct.Pull  = GPIO_NOPULL;
  HAL_GPIO_Init(AUDIO_RESET_GPIO, &GPIO_InitStruct);

  /* I2C bus init */
  //I2C1_Init();

  /* Power Down the codec */
  CODEC_AUDIO_POWER_OFF();

  /* wait for a delay to insure registers erasing */
  HAL_Delay(5);

  /* Power on the codec */
  CODEC_AUDIO_POWER_ON();

  /* wait for a delay to insure registers erasing */
  HAL_Delay(5);
}

/**
  * @brief  Deinitializes Audio low level.
  * @retval None
  */
void AUDIO_IO_DeInit(void)                       /* TO DO */
{
  GPIO_InitTypeDef  GPIO_InitStruct;

  /***********************************************************************/
  /* In case of battery-supplied powered, there is no audio codec-based
     features available. Set audio codec I/O default setting */
  /***********************************************************************/
  __HAL_RCC_GPIOE_CLK_ENABLE();
  GPIO_InitStruct.Mode      = GPIO_MODE_OUTPUT_PP  ;
  GPIO_InitStruct.Pin       = (GPIO_PIN_2 | GPIO_PIN_3 | GPIO_PIN_4 | GPIO_PIN_5 | GPIO_PIN_6);
  GPIO_InitStruct.Pull      = GPIO_PULLDOWN;
  GPIO_InitStruct.Speed     = GPIO_SPEED_FREQ_VERY_HIGH;
  HAL_GPIO_Init(GPIOE, &GPIO_InitStruct);
  HAL_GPIO_WritePin(GPIOE, GPIO_PIN_2, GPIO_PIN_RESET);
  HAL_GPIO_WritePin(GPIOE, GPIO_PIN_3, GPIO_PIN_RESET);
  HAL_GPIO_WritePin(GPIOE, GPIO_PIN_4, GPIO_PIN_RESET);
  HAL_GPIO_WritePin(GPIOE, GPIO_PIN_5, GPIO_PIN_RESET);
  HAL_GPIO_WritePin(GPIOE, GPIO_PIN_6, GPIO_PIN_RESET);

  /* I2C bus Deinit */
  //I2C1_DeInit();
}

/**
  * @brief  Writes a single data.
  * @param  Addr: I2C address
  * @param  Reg: Reg address
  * @param  Value: Data to be written
  * @retval None
  */
void AUDIO_IO_Write(uint8_t Addr, uint8_t Reg, uint8_t Value)
{

	HAL_I2C_Mem_Write(&hi2c1, Addr, (uint16_t)Reg, I2C_MEMADD_SIZE_8BIT, &Value, 1, 100);

}

/**
  * @brief  Reads a single data.
  * @param  Addr: I2C address
  * @param  Reg: Reg address
  * @retval Data to be read
  */
uint8_t AUDIO_IO_Read(uint8_t Addr, uint8_t Reg)
{
  uint8_t Read_Value = 0;

  HAL_I2C_Mem_Read(&hi2c1, Addr, (uint16_t)Reg, I2C_MEMADD_SIZE_8BIT, &Read_Value, 1, 100);

  return Read_Value;
}

/**
  * @brief  AUDIO Codec delay
  * @param  Delay: Delay in ms
  * @retval None
  */
void AUDIO_IO_Delay(uint32_t Delay)
{
  HAL_Delay(Delay);
}

/* USER CODE END 0 */

int main(void)
{

  /* MCU Configuration--------------------------------------------------------*/

  /* Reset of all peripherals, Initializes the Flash interface and the Systick. */
  HAL_Init();

  /* Configure the system clock */
  SystemClock_Config();

  /* Initialize all configured peripherals */
  MX_GPIO_Init();
  MX_DMA_Init();
  MX_I2C1_Init();
  MX_I2C2_Init();
  MX_LCD_Init();
  MX_QUADSPI_Init();
  MX_USART2_UART_Init();
  MX_TIM6_Init();
  MX_TIM7_Init();
  MX_DFSDM1_Init();
  MX_SAI1_Init();
  /* USER CODE BEGIN 2 */

  //HAL_GPIO_WritePin(M3V3_REG_ON_GPIO_Port,M3V3_REG_ON_Pin,GPIO_PIN_SET);

  HAL_Delay(2000);

  N25_flash_read(&hqspi,(uint8_t*)&config,0x00,sizeof(modulus_config_t));

  audio_init();

  // load config from flash

  if(config.first_write != 1)
  {

	  config.mode=0;
	  config.volume=150;
	  config.contrast=255;

  }

  LCD_SetContrast(&hlcd,config.contrast);

  //cs43l22_set_volume(config.volume);

  LCD_DisplayStr(&hlcd,"HELLO");

  HAL_Delay(2000);

  switchScreen();

  // Start ADC DMA recive
  //HAL_StatusTypeDef err=HAL_SAI_Receive_DMA(&hsai_BlockB1,(uint8_t*)dma_rx_buffer,DMA_RX_BUFFER_SIZE*2*sizeof(uint32_t));
  HAL_StatusTypeDef err=HAL_DFSDM_FilterRegularStart_DMA(&hdfsdm1_filter0, dma_rx_buffer, DMA_RX_BUFFER_SIZE*2);

  if(err!=HAL_OK)
  {
	  const char *msg="Something went wrong!";

	  HAL_UART_Transmit(&huart2,(const uint8_t*)msg,strlen(msg),100);
  }
  /* USER CODE END 2 */

  /* Infinite loop */
  /* USER CODE BEGIN WHILE */

  while (1)
  {
	  if(ModeChanged)
	  {
		  switchScreen();

		  ModeChanged=false;
	  }

	  if(LCDRefresh)
	  {
		  displayScreen();

		  LCDRefresh=false;
	  }

	  if(UpdateSettings)
	  {
		  // update contrast
		  LCD_SetContrast(&hlcd,config.contrast);
		  // update volume in DAC
		  cs43l22_SetVolume(AUDIO_I2C_ADDR,config.volume);

		  UpdateSettings=false;
	  }

	  if(SaveSettings)
	  {
		  SaveSettings=false;

		  config.first_write=1;

		  N25_flash_write(&hqspi,(uint8_t*)&config,0x00,sizeof(modulus_config_t));

	  }

	  if(ProcessAudio)
	  	  {
	  		  // pass it to function
	  		  int32_t* dma_buffer = getBuffer();

	  		  //HAL_SAI_Receive_DMA(&hsai_BlockB1,current_dma_buffer,DMA_RX_BUFFER_SIZE*2);
	  		  from_uint8_to_floats(dma_buffer,audio_input_buffer);
	  		  // function to process audio
	  		  char msg[100]={0};

	  		  modes_list[config.mode](audio_input_buffer,audio_output_buffer);

	  		  /* Audio to DAC*/
	  		  sprintf(msg,"Hello %d \n",dma_buffer[0]);

	  		  HAL_UART_Transmit(&huart2,(const uint8_t*)msg,strlen(msg),100);

	  		  ProcessAudio=false;

	  		/*for(size_t i=0;i<(DMA_RX_BUFFER_SIZE);++i)
	  		{
	  			dma_tx_buffer[i*2] = SaturaLH((dma_buffer[i] >> 8), -32768, 32767);
	  			dma_tx_buffer[i*2 + 1]=dma_tx_buffer[i*2];
	  		}*/
	  		  from_float_to_uint8(audio_output_buffer, dma_tx_buffer, DMA_TX_BUFFER_SIZE);

	  		  audio_drv->Play(AUDIO_I2C_ADDR, (uint16_t *) dma_tx_buffer, DMA_TX_BUFFER_SIZE*2);

	  	      HAL_SAI_Transmit_DMA(&hsai_BlockA1, (uint8_t*)dma_tx_buffer, DMA_TX_BUFFER_SIZE*2);

	  	  }
    /* USER CODE END WHILE */

  }
}

void SystemClock_Config(void)
{
  RCC_OscInitTypeDef RCC_OscInitStruct = {0};
  RCC_ClkInitTypeDef RCC_ClkInitStruct = {0};

  /** Configure the main internal regulator output voltage
  */
  if (HAL_PWREx_ControlVoltageScaling(PWR_REGULATOR_VOLTAGE_SCALE1) != HAL_OK)
  {
    Error_Handler();
  }

  /** Configure LSE Drive Capability
  */
  HAL_PWR_EnableBkUpAccess();
  __HAL_RCC_LSEDRIVE_CONFIG(RCC_LSEDRIVE_LOW);

  /** Initializes the RCC Oscillators according to the specified parameters
  * in the RCC_OscInitTypeDef structure.
  */
  RCC_OscInitStruct.OscillatorType = RCC_OSCILLATORTYPE_LSI|RCC_OSCILLATORTYPE_LSE
                              |RCC_OSCILLATORTYPE_MSI;
  RCC_OscInitStruct.LSEState = RCC_LSE_ON;
  RCC_OscInitStruct.LSIState = RCC_LSI_ON;
  RCC_OscInitStruct.MSIState = RCC_MSI_ON;
  RCC_OscInitStruct.MSICalibrationValue = 0;
  RCC_OscInitStruct.MSIClockRange = RCC_MSIRANGE_6;
  RCC_OscInitStruct.PLL.PLLState = RCC_PLL_ON;
  RCC_OscInitStruct.PLL.PLLSource = RCC_PLLSOURCE_MSI;
  RCC_OscInitStruct.PLL.PLLM = 1;
  RCC_OscInitStruct.PLL.PLLN = 20;
  RCC_OscInitStruct.PLL.PLLP = RCC_PLLP_DIV7;
  RCC_OscInitStruct.PLL.PLLQ = RCC_PLLQ_DIV2;
  RCC_OscInitStruct.PLL.PLLR = RCC_PLLR_DIV2;
  if (HAL_RCC_OscConfig(&RCC_OscInitStruct) != HAL_OK)
  {
    Error_Handler();
  }

  /** Initializes the CPU, AHB and APB buses clocks
  */
  RCC_ClkInitStruct.ClockType = RCC_CLOCKTYPE_HCLK|RCC_CLOCKTYPE_SYSCLK
                              |RCC_CLOCKTYPE_PCLK1|RCC_CLOCKTYPE_PCLK2;
  RCC_ClkInitStruct.SYSCLKSource = RCC_SYSCLKSOURCE_PLLCLK;
  RCC_ClkInitStruct.AHBCLKDivider = RCC_SYSCLK_DIV2;
  RCC_ClkInitStruct.APB1CLKDivider = RCC_HCLK_DIV1;
  RCC_ClkInitStruct.APB2CLKDivider = RCC_HCLK_DIV1;

  if (HAL_RCC_ClockConfig(&RCC_ClkInitStruct, FLASH_LATENCY_1) != HAL_OK)
  {
    Error_Handler();
  }

  /** Enable MSI Auto calibration
  */
  HAL_RCCEx_EnableMSIPLLMode();
}

static void MX_DFSDM1_Init(void)
{

  hdfsdm1_filter0.Instance = DFSDM1_Filter0;
  hdfsdm1_filter0.Init.RegularParam.Trigger = DFSDM_FILTER_SW_TRIGGER;
  hdfsdm1_filter0.Init.RegularParam.FastMode = ENABLE;
  hdfsdm1_filter0.Init.RegularParam.DmaMode = ENABLE;
  hdfsdm1_filter0.Init.InjectedParam.Trigger = DFSDM_FILTER_SW_TRIGGER;
  hdfsdm1_filter0.Init.InjectedParam.ScanMode = ENABLE;
  hdfsdm1_filter0.Init.InjectedParam.DmaMode = DISABLE;
  hdfsdm1_filter0.Init.InjectedParam.ExtTrigger = DFSDM_FILTER_EXT_TRIG_TIM1_TRGO;
  hdfsdm1_filter0.Init.InjectedParam.ExtTriggerEdge = DFSDM_FILTER_EXT_TRIG_RISING_EDGE;
  hdfsdm1_filter0.Init.FilterParam.SincOrder = DFSDM_FILTER_SINC3_ORDER;
  hdfsdm1_filter0.Init.FilterParam.Oversampling = 64;
  hdfsdm1_filter0.Init.FilterParam.IntOversampling = 1;
  if (HAL_DFSDM_FilterInit(&hdfsdm1_filter0) != HAL_OK)
  {
    Error_Handler();
  }
  hdfsdm1_channel2.Instance = DFSDM1_Channel2;
  hdfsdm1_channel2.Init.OutputClock.Activation = ENABLE;
  hdfsdm1_channel2.Init.OutputClock.Selection = DFSDM_CHANNEL_OUTPUT_CLOCK_AUDIO;
  hdfsdm1_channel2.Init.OutputClock.Divider = 4;
  hdfsdm1_channel2.Init.Input.Multiplexer = DFSDM_CHANNEL_EXTERNAL_INPUTS;
  hdfsdm1_channel2.Init.Input.DataPacking = DFSDM_CHANNEL_STANDARD_MODE;
  hdfsdm1_channel2.Init.Input.Pins = DFSDM_CHANNEL_SAME_CHANNEL_PINS;
  hdfsdm1_channel2.Init.SerialInterface.Type = DFSDM_CHANNEL_SPI_RISING;
  hdfsdm1_channel2.Init.SerialInterface.SpiClock = DFSDM_CHANNEL_SPI_CLOCK_INTERNAL;
  hdfsdm1_channel2.Init.Awd.FilterOrder = DFSDM_CHANNEL_FASTSINC_ORDER;
  hdfsdm1_channel2.Init.Awd.Oversampling = 10;
  hdfsdm1_channel2.Init.Offset = 0;
  hdfsdm1_channel2.Init.RightBitShift = 2;
  if (HAL_DFSDM_ChannelInit(&hdfsdm1_channel2) != HAL_OK)
  {
    Error_Handler();
  }
  if (HAL_DFSDM_FilterConfigRegChannel(&hdfsdm1_filter0, DFSDM_CHANNEL_2, DFSDM_CONTINUOUS_CONV_ON) != HAL_OK)
  {
    Error_Handler();
  }
  if (HAL_DFSDM_FilterConfigInjChannel(&hdfsdm1_filter0, DFSDM_CHANNEL_2) != HAL_OK)
  {
    Error_Handler();
  }

}

static void MX_I2C1_Init(void)
{

  hi2c1.Instance = I2C1;
  hi2c1.Init.Timing = 0x00404C74;
  hi2c1.Init.OwnAddress1 = 0;
  hi2c1.Init.AddressingMode = I2C_ADDRESSINGMODE_7BIT;
  hi2c1.Init.DualAddressMode = I2C_DUALADDRESS_DISABLE;
  hi2c1.Init.OwnAddress2 = 0;
  hi2c1.Init.OwnAddress2Masks = I2C_OA2_NOMASK;
  hi2c1.Init.GeneralCallMode = I2C_GENERALCALL_DISABLE;
  hi2c1.Init.NoStretchMode = I2C_NOSTRETCH_DISABLE;
  if (HAL_I2C_Init(&hi2c1) != HAL_OK)
  {
    Error_Handler();
  }

  /** Configure Analogue filter
  */
  if (HAL_I2CEx_ConfigAnalogFilter(&hi2c1, I2C_ANALOGFILTER_ENABLE) != HAL_OK)
  {
    Error_Handler();
  }

  /** Configure Digital filter
  */
  if (HAL_I2CEx_ConfigDigitalFilter(&hi2c1, 0) != HAL_OK)
  {
    Error_Handler();
  }

}

static void MX_I2C2_Init(void)
{

  hi2c2.Instance = I2C2;
  hi2c2.Init.Timing = 0x00404C74;
  hi2c2.Init.OwnAddress1 = 0;
  hi2c2.Init.AddressingMode = I2C_ADDRESSINGMODE_7BIT;
  hi2c2.Init.DualAddressMode = I2C_DUALADDRESS_DISABLE;
  hi2c2.Init.OwnAddress2 = 0;
  hi2c2.Init.OwnAddress2Masks = I2C_OA2_NOMASK;
  hi2c2.Init.GeneralCallMode = I2C_GENERALCALL_DISABLE;
  hi2c2.Init.NoStretchMode = I2C_NOSTRETCH_DISABLE;
  if (HAL_I2C_Init(&hi2c2) != HAL_OK)
  {
    Error_Handler();
  }

  /** Configure Analogue filter
  */
  if (HAL_I2CEx_ConfigAnalogFilter(&hi2c2, I2C_ANALOGFILTER_ENABLE) != HAL_OK)
  {
    Error_Handler();
  }

  /** Configure Digital filter
  */
  if (HAL_I2CEx_ConfigDigitalFilter(&hi2c2, 0) != HAL_OK)
  {
    Error_Handler();
  }

}

static void MX_LCD_Init(void)
{

  hlcd.Instance = LCD;
  hlcd.Init.Prescaler = LCD_PRESCALER_1;
  hlcd.Init.Divider = LCD_DIVIDER_16;
  hlcd.Init.Duty = LCD_DUTY_1_4;
  hlcd.Init.Bias = LCD_BIAS_1_4;
  hlcd.Init.VoltageSource = LCD_VOLTAGESOURCE_INTERNAL;
  hlcd.Init.Contrast = LCD_CONTRASTLEVEL_0;
  hlcd.Init.DeadTime = LCD_DEADTIME_0;
  hlcd.Init.PulseOnDuration = LCD_PULSEONDURATION_0;
  hlcd.Init.MuxSegment = LCD_MUXSEGMENT_DISABLE;
  hlcd.Init.BlinkMode = LCD_BLINKMODE_OFF;
  hlcd.Init.BlinkFrequency = LCD_BLINKFREQUENCY_DIV8;
  hlcd.Init.HighDrive = LCD_HIGHDRIVE_DISABLE;
  if (HAL_LCD_Init(&hlcd) != HAL_OK)
  {
    Error_Handler();
  }

}

static void MX_QUADSPI_Init(void)
{

  /* QUADSPI parameter configuration*/
  hqspi.Instance = QUADSPI;
  hqspi.Init.ClockPrescaler = 1;
  hqspi.Init.FifoThreshold = 4;
  hqspi.Init.SampleShifting = QSPI_SAMPLE_SHIFTING_HALFCYCLE;
  hqspi.Init.FlashSize = 24;
  hqspi.Init.ChipSelectHighTime = QSPI_CS_HIGH_TIME_1_CYCLE;
  hqspi.Init.ClockMode = QSPI_CLOCK_MODE_0;
  if (HAL_QSPI_Init(&hqspi) != HAL_OK)
  {
    Error_Handler();
  }

}

static void MX_SAI1_Init(void)
{

  hsai_BlockA1.Instance = SAI1_Block_A;
  hsai_BlockA1.Init.Protocol = SAI_FREE_PROTOCOL;
  hsai_BlockA1.Init.AudioMode = SAI_MODEMASTER_TX;
  hsai_BlockA1.Init.DataSize = SAI_DATASIZE_16;
  hsai_BlockA1.Init.FirstBit = SAI_FIRSTBIT_MSB;
  hsai_BlockA1.Init.ClockStrobing = SAI_CLOCKSTROBING_FALLINGEDGE;
  hsai_BlockA1.Init.Synchro = SAI_ASYNCHRONOUS;
  hsai_BlockA1.Init.OutputDrive = SAI_OUTPUTDRIVE_ENABLE;
  hsai_BlockA1.Init.NoDivider = SAI_MASTERDIVIDER_ENABLE;
  hsai_BlockA1.Init.FIFOThreshold = SAI_FIFOTHRESHOLD_1QF;
  hsai_BlockA1.Init.AudioFrequency = SAI_AUDIO_FREQUENCY_44K;
  hsai_BlockA1.Init.SynchroExt = SAI_SYNCEXT_DISABLE;
  hsai_BlockA1.Init.MonoStereoMode = SAI_STEREOMODE;
  hsai_BlockA1.Init.CompandingMode = SAI_NOCOMPANDING;
  hsai_BlockA1.Init.TriState = SAI_OUTPUT_NOTRELEASED;
  hsai_BlockA1.FrameInit.FrameLength = 32;
  hsai_BlockA1.FrameInit.ActiveFrameLength = 16;
  hsai_BlockA1.FrameInit.FSDefinition = SAI_FS_CHANNEL_IDENTIFICATION;
  hsai_BlockA1.FrameInit.FSPolarity = SAI_FS_ACTIVE_LOW;
  hsai_BlockA1.FrameInit.FSOffset = SAI_FS_BEFOREFIRSTBIT;
  hsai_BlockA1.SlotInit.FirstBitOffset = 0;
  hsai_BlockA1.SlotInit.SlotSize = SAI_SLOTSIZE_DATASIZE;
  hsai_BlockA1.SlotInit.SlotNumber = 2;
  hsai_BlockA1.SlotInit.SlotActive = 0x00000003;
  if (HAL_SAI_Init(&hsai_BlockA1) != HAL_OK)
  {
    Error_Handler();
  }

}

static void MX_TIM6_Init(void)
{

  TIM_MasterConfigTypeDef sMasterConfig = {0};

  htim6.Instance = TIM6;
  htim6.Init.Prescaler = 1000;
  htim6.Init.CounterMode = TIM_COUNTERMODE_UP;
  htim6.Init.Period = 65535;
  htim6.Init.AutoReloadPreload = TIM_AUTORELOAD_PRELOAD_DISABLE;
  if (HAL_TIM_Base_Init(&htim6) != HAL_OK)
  {
    Error_Handler();
  }
  sMasterConfig.MasterOutputTrigger = TIM_TRGO_RESET;
  sMasterConfig.MasterSlaveMode = TIM_MASTERSLAVEMODE_DISABLE;
  if (HAL_TIMEx_MasterConfigSynchronization(&htim6, &sMasterConfig) != HAL_OK)
  {
    Error_Handler();
  }

}

static void MX_TIM7_Init(void)
{

  TIM_MasterConfigTypeDef sMasterConfig = {0};

  htim7.Instance = TIM7;
  htim7.Init.Prescaler = 250;
  htim7.Init.CounterMode = TIM_COUNTERMODE_UP;
  htim7.Init.Period = 65535;
  htim7.Init.AutoReloadPreload = TIM_AUTORELOAD_PRELOAD_DISABLE;
  if (HAL_TIM_Base_Init(&htim7) != HAL_OK)
  {
    Error_Handler();
  }
  sMasterConfig.MasterOutputTrigger = TIM_TRGO_RESET;
  sMasterConfig.MasterSlaveMode = TIM_MASTERSLAVEMODE_DISABLE;
  if (HAL_TIMEx_MasterConfigSynchronization(&htim7, &sMasterConfig) != HAL_OK)
  {
    Error_Handler();
  }

}

static void MX_USART2_UART_Init(void)
{

  huart2.Instance = USART2;
  huart2.Init.BaudRate = 115200;
  huart2.Init.WordLength = UART_WORDLENGTH_8B;
  huart2.Init.StopBits = UART_STOPBITS_1;
  huart2.Init.Parity = UART_PARITY_NONE;
  huart2.Init.Mode = UART_MODE_TX_RX;
  huart2.Init.HwFlowCtl = UART_HWCONTROL_NONE;
  huart2.Init.OverSampling = UART_OVERSAMPLING_16;
  huart2.Init.OneBitSampling = UART_ONE_BIT_SAMPLE_DISABLE;
  huart2.AdvancedInit.AdvFeatureInit = UART_ADVFEATURE_NO_INIT;
  if (HAL_UART_Init(&huart2) != HAL_OK)
  {
    Error_Handler();
  }

}

static void MX_DMA_Init(void)
{

  /* DMA controller clock enable */
  __HAL_RCC_DMA2_CLK_ENABLE();
  __HAL_RCC_DMA1_CLK_ENABLE();

  /* DMA interrupt init */
  /* DMA1_Channel4_IRQn interrupt configuration */
  HAL_NVIC_SetPriority(DMA1_Channel4_IRQn, 0, 0);
  HAL_NVIC_EnableIRQ(DMA1_Channel4_IRQn);
  /* DMA2_Channel1_IRQn interrupt configuration */
  HAL_NVIC_SetPriority(DMA2_Channel1_IRQn, 0, 0);
  HAL_NVIC_EnableIRQ(DMA2_Channel1_IRQn);

}

static void MX_GPIO_Init(void)
{
  GPIO_InitTypeDef GPIO_InitStruct = {0};

  /* GPIO Ports Clock Enable */
  __HAL_RCC_GPIOE_CLK_ENABLE();
  __HAL_RCC_GPIOC_CLK_ENABLE();
  __HAL_RCC_GPIOH_CLK_ENABLE();
  __HAL_RCC_GPIOA_CLK_ENABLE();
  __HAL_RCC_GPIOB_CLK_ENABLE();
  __HAL_RCC_GPIOD_CLK_ENABLE();

  /*Configure GPIO pin Output Level */
  HAL_GPIO_WritePin(GPIOE, AUDIO_RST_Pin|XL_CS_Pin, GPIO_PIN_RESET);

  /*Configure GPIO pin Output Level */
  HAL_GPIO_WritePin(GPIOB, LD_R_Pin|M3V3_REG_ON_Pin, GPIO_PIN_RESET);

  /*Configure GPIO pin Output Level */
  HAL_GPIO_WritePin(OTG_FS_PowerSwitchOn_GPIO_Port, OTG_FS_PowerSwitchOn_Pin, GPIO_PIN_SET);

  /*Configure GPIO pin Output Level */
  HAL_GPIO_WritePin(OTG_FS_VBUS_GPIO_Port, OTG_FS_VBUS_Pin, GPIO_PIN_RESET);

  /*Configure GPIO pin Output Level */
  HAL_GPIO_WritePin(GYRO_CS_GPIO_Port, GYRO_CS_Pin, GPIO_PIN_RESET);

  /*Configure GPIO pin : AUDIO_RST_Pin */
  GPIO_InitStruct.Pin = AUDIO_RST_Pin;
  GPIO_InitStruct.Mode = GPIO_MODE_OUTPUT_PP;
  GPIO_InitStruct.Pull = GPIO_NOPULL;
  GPIO_InitStruct.Speed = GPIO_SPEED_FREQ_HIGH;
  HAL_GPIO_Init(AUDIO_RST_GPIO_Port, &GPIO_InitStruct);

  /*Configure GPIO pins : MFX_IRQ_OUT_Pin OTG_FS_OverCurrent_Pin */
  GPIO_InitStruct.Pin = MFX_IRQ_OUT_Pin|OTG_FS_OverCurrent_Pin;
  GPIO_InitStruct.Mode = GPIO_MODE_EVT_RISING;
  GPIO_InitStruct.Pull = GPIO_NOPULL;
  HAL_GPIO_Init(GPIOC, &GPIO_InitStruct);

  /*Configure GPIO pins : PC0 MAG_INT_Pin MAG_DRDY_Pin */
  GPIO_InitStruct.Pin = GPIO_PIN_0|MAG_INT_Pin|MAG_DRDY_Pin;
  GPIO_InitStruct.Mode = GPIO_MODE_INPUT;
  GPIO_InitStruct.Pull = GPIO_NOPULL;
  HAL_GPIO_Init(GPIOC, &GPIO_InitStruct);

  /*Configure GPIO pin : JOY_CENTER_Pin */
  GPIO_InitStruct.Pin = JOY_CENTER_Pin;
  GPIO_InitStruct.Mode = GPIO_MODE_IT_RISING;
  GPIO_InitStruct.Pull = GPIO_NOPULL;
  HAL_GPIO_Init(JOY_CENTER_GPIO_Port, &GPIO_InitStruct);

  /*Configure GPIO pins : JOY_LEFT_Pin JOY_RIGHT_Pin JOY_UP_Pin JOY_DOWN_Pin */
  GPIO_InitStruct.Pin = JOY_LEFT_Pin|JOY_RIGHT_Pin|JOY_UP_Pin|JOY_DOWN_Pin;
  GPIO_InitStruct.Mode = GPIO_MODE_IT_RISING;
  GPIO_InitStruct.Pull = GPIO_PULLDOWN;
  HAL_GPIO_Init(GPIOA, &GPIO_InitStruct);

  /*Configure GPIO pin : MFX_WAKEUP_Pin */
  GPIO_InitStruct.Pin = MFX_WAKEUP_Pin;
  GPIO_InitStruct.Mode = GPIO_MODE_EVT_RISING;
  GPIO_InitStruct.Pull = GPIO_NOPULL;
  HAL_GPIO_Init(MFX_WAKEUP_GPIO_Port, &GPIO_InitStruct);

  /*Configure GPIO pin : LD_R_Pin */
  GPIO_InitStruct.Pin = LD_R_Pin;
  GPIO_InitStruct.Mode = GPIO_MODE_OUTPUT_PP;
  GPIO_InitStruct.Pull = GPIO_PULLUP;
  GPIO_InitStruct.Speed = GPIO_SPEED_FREQ_VERY_HIGH;
  HAL_GPIO_Init(LD_R_GPIO_Port, &GPIO_InitStruct);

  /*Configure GPIO pins : OTG_FS_PowerSwitchOn_Pin OTG_FS_VBUS_Pin */
  GPIO_InitStruct.Pin = OTG_FS_PowerSwitchOn_Pin|OTG_FS_VBUS_Pin;
  GPIO_InitStruct.Mode = GPIO_MODE_OUTPUT_PP;
  GPIO_InitStruct.Pull = GPIO_NOPULL;
  GPIO_InitStruct.Speed = GPIO_SPEED_FREQ_LOW;
  HAL_GPIO_Init(GPIOC, &GPIO_InitStruct);

  /*Configure GPIO pins : OTG_FS_DM_Pin OTG_FS_DP_Pin */
  GPIO_InitStruct.Pin = OTG_FS_DM_Pin|OTG_FS_DP_Pin;
  GPIO_InitStruct.Mode = GPIO_MODE_AF_PP;
  GPIO_InitStruct.Pull = GPIO_NOPULL;
  GPIO_InitStruct.Speed = GPIO_SPEED_FREQ_VERY_HIGH;
  GPIO_InitStruct.Alternate = GPIO_AF10_OTG_FS;
  HAL_GPIO_Init(GPIOA, &GPIO_InitStruct);

  /*Configure GPIO pins : MEMS_SCK_Pin MEMS_MISO_Pin MEMS_MOSI_Pin */
  GPIO_InitStruct.Pin = MEMS_SCK_Pin|MEMS_MISO_Pin|MEMS_MOSI_Pin;
  GPIO_InitStruct.Mode = GPIO_MODE_AF_PP;
  GPIO_InitStruct.Pull = GPIO_NOPULL;
  GPIO_InitStruct.Speed = GPIO_SPEED_FREQ_VERY_HIGH;
  GPIO_InitStruct.Alternate = GPIO_AF5_SPI2;
  HAL_GPIO_Init(GPIOD, &GPIO_InitStruct);

  /*Configure GPIO pin : GYRO_CS_Pin */
  GPIO_InitStruct.Pin = GYRO_CS_Pin;
  GPIO_InitStruct.Mode = GPIO_MODE_OUTPUT_PP;
  GPIO_InitStruct.Pull = GPIO_NOPULL;
  GPIO_InitStruct.Speed = GPIO_SPEED_FREQ_VERY_HIGH;
  HAL_GPIO_Init(GYRO_CS_GPIO_Port, &GPIO_InitStruct);

  /*Configure GPIO pin : M3V3_REG_ON_Pin */
  GPIO_InitStruct.Pin = M3V3_REG_ON_Pin;
  GPIO_InitStruct.Mode = GPIO_MODE_OUTPUT_PP;
  GPIO_InitStruct.Pull = GPIO_NOPULL;
  GPIO_InitStruct.Speed = GPIO_SPEED_FREQ_LOW;
  HAL_GPIO_Init(M3V3_REG_ON_GPIO_Port, &GPIO_InitStruct);

  /*Configure GPIO pin : GYRO_INT2_Pin */
  GPIO_InitStruct.Pin = GYRO_INT2_Pin;
  GPIO_InitStruct.Mode = GPIO_MODE_EVT_RISING;
  GPIO_InitStruct.Pull = GPIO_NOPULL;
  HAL_GPIO_Init(GYRO_INT2_GPIO_Port, &GPIO_InitStruct);

  /*Configure GPIO pin : XL_CS_Pin */
  GPIO_InitStruct.Pin = XL_CS_Pin;
  GPIO_InitStruct.Mode = GPIO_MODE_OUTPUT_PP;
  GPIO_InitStruct.Pull = GPIO_NOPULL;
  GPIO_InitStruct.Speed = GPIO_SPEED_FREQ_LOW;
  HAL_GPIO_Init(XL_CS_GPIO_Port, &GPIO_InitStruct);

  /* EXTI interrupt init*/
  HAL_NVIC_SetPriority(EXTI0_IRQn, 0, 0);
  HAL_NVIC_EnableIRQ(EXTI0_IRQn);

  HAL_NVIC_SetPriority(EXTI1_IRQn, 0, 0);
  HAL_NVIC_EnableIRQ(EXTI1_IRQn);

  HAL_NVIC_SetPriority(EXTI2_IRQn, 0, 0);
  HAL_NVIC_EnableIRQ(EXTI2_IRQn);

  HAL_NVIC_SetPriority(EXTI3_IRQn, 0, 0);
  HAL_NVIC_EnableIRQ(EXTI3_IRQn);

  HAL_NVIC_SetPriority(EXTI9_5_IRQn, 0, 0);
  HAL_NVIC_EnableIRQ(EXTI9_5_IRQn);

}

void Error_Handler(void)
{
  __disable_irq();
  while (1)
  {
  }
}
